# FM33L0XXD register map
File version: 1.0
CPU: SC000 r1p0, little endian, no MPU, FPU, 8 interrupt priority bits
Registers are 32-bit, read-write, reset 0x0 unless marked. A register's access mark holds for its fields unless they carry their own. Offsets are from the block's base; [hi:lo] are bit positions; {n}, {i} and the like mark numbered series.

## COMPCOM — COMPCOM module information
Base 0x40012848
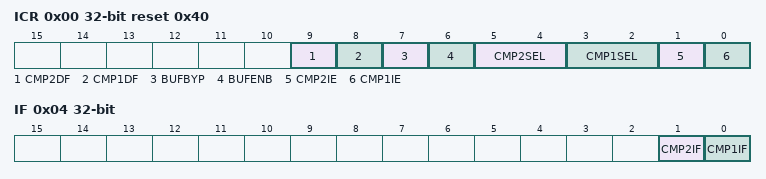
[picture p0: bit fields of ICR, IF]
0x00 ICR reset 0x40
  [9] CMP2DF — CMP2DF field description
  [8] CMP1DF — CMP1DF field description
  [7] BUFBYP — BUFBYP field description
  [6] BUFENB — BUFENB field description
  [5:4] CMP2SEL — CMP2SEL field description
  [3:2] CMP1SEL — CMP1SEL field description
  [1] CMP2IE — CMP2IE field description
  [0] CMP1IE — CMP1IE field description
0x04 IF
  [1] CMP2IF — CMP2IF field description
  [0] CMP1IF — CMP1IF field description

## CRC — CRC module information
Base 0x40010000
0x00 CRCDR reset 0xFFFFFFFF
  [31:0] CRCDR — CRCDR field description
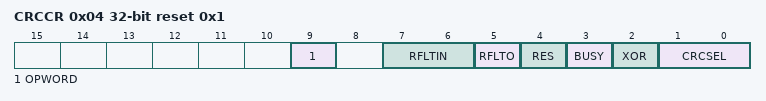
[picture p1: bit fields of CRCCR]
0x04 CRCCR reset 0x1
  [9] OPWORD — OP_WORD field description
  [7:6] RFLTIN — RFLTIN field description
  [5] RFLTO — RFLTO field description
  [4] RES ro — RES field description
  [3] BUSY ro — BUSY field description
  [2] XOR — XOR field description
  [1:0] CRCSEL — CRCSEL field description
0x08 CRCCAL reset 0xFFFFFFFF
  [31:0] LFSR — LFSR field description
0x0C CRCXOR
  [31:0] XOR — CRC_XOR field description
0x1C CRCPOLY reset 0x1021
  [31:0] POLY — CRC_POLY field description

## DBG — DBG module information
Base 0x40000000
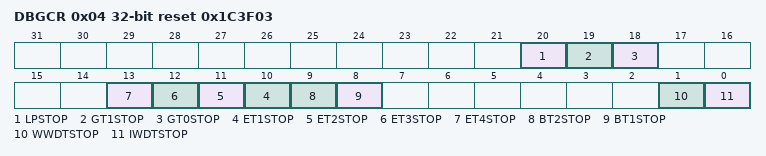
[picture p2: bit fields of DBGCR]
0x04 DBGCR reset 0x1C3F03
  [20] LPSTOP — LP_STOP field description
  [19] GT1STOP — GT1_STOP field description
  [18] GT0STOP — GT0_STOP field description
  [n+9] ET{n}STOP (n=1..4) — ET{n}_STOP field description
  [9] BT2STOP — BT2_STOP field description
  [8] BT1STOP — BT1_STOP field description
  [1] WWDTSTOP — WWDT_STOP field description
  [0] IWDTSTOP — IWDT_STOP field description

## DISP — DISP module information
Base 0x40010C00
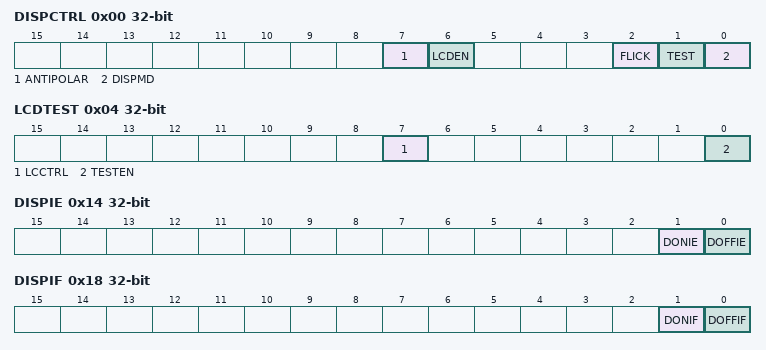
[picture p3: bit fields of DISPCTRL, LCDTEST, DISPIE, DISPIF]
0x00 DISPCTRL
  [7] ANTIPOLAR — ANTIPOLAR field description
  [6] LCDEN — LCDEN field description
  [2] FLICK — FLICK field description
  [1] TEST — TEST field description
  [0] DISPMD — DISPMD field description
0x04 LCDTEST
  [7] LCCTRL — LCCTRL field description
  [0] TESTEN — TESTEN field description
0x08 DF
  [7:0] DF — DF field description
0x0C TON
  [7:0] TON — TON field description
0x10 TOFF
  [7:0] TOFF — TOFF field description
0x14 DISPIE
  [1] DONIE — DONIE field description
  [0] DOFFIE — DOFFIE field description
0x18 DISPIF
  [1] DONIF — DONIF field description
  [0] DOFFIF — DOFFIF field description
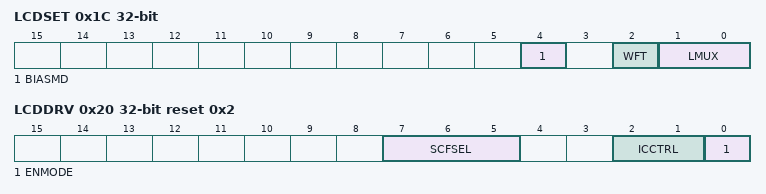
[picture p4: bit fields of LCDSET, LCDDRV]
0x1C LCDSET
  [4] BIASMD — BIASMD field description
  [2] WFT — WFT field description
  [1:0] LMUX — LMUX field description
0x20 LCDDRV reset 0x2
  [7:5] SCFSEL — SCFSEL field description
  [2:1] ICCTRL — IC_CTRL field description
  [0] ENMODE — ENMODE field description
{0x24+4i} DISPDATA{i} (i=0..9)
  [31:0] DSDA{i} — DSDA{i} field description
0x4C LCDBIAS
  [3:0] DSDA9 — DSDA9 field description
0x50 COMEN
  [3:0] COMEN — COMEN field description
0x54 SEGEN0
  [31:0] SEGEN0 — SEGEN0 field description
0x58 SEGEN1
  [11:0] SEGEN1 — SEGEN1 field description

## DMAC — DMAC module information
Base 0x40000400
0x00 GLOBALCTRL
  [0] DMACENABLE — DMACENABLE field description
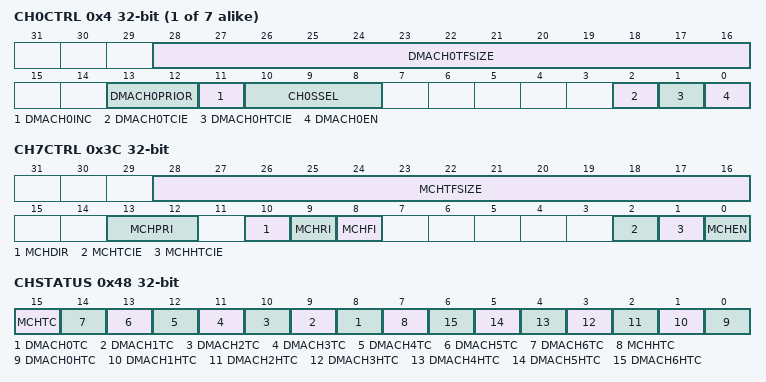
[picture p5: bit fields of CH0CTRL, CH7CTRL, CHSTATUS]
{0x4+8i} CH{i}CTRL (i=0..6)
  [28:16] DMACH{i}TFSIZE — DMACH{i}_TFSIZE field description
  [13:12] DMACH{i}PRIOR — DMACH{i}_PRIOR field description
  [11] DMACH{i}INC — DMACH{i}_INC field description
  [10:8] CH{i}SSEL — CH{i}_SSEL field description
  [2] DMACH{i}TCIE — DMACH{i}_TC_IE field description
  [1] DMACH{i}HTCIE — DMACH{i}_HTC_IE field description
  [0] DMACH{i}EN — DMACH{i}_EN field description
{0x8+8i} CH{i}RAMADDR (i=0..6)
  [14:0] DMACH{i}ADDR — DMACH{i}_ADDR field description
0x3C CH7CTRL
  [28:16] MCHTFSIZE — MCHTFSIZE field description
  [13:12] MCHPRI — MCHPRI field description
  [10] MCHDIR — MCHDIR field description
  [9] MCHRI — MCHRI field description
  [8] MCHFI — MCHFI field description
  [2] MCHTCIE — MCHTC_IE field description
  [1] MCHHTCIE — MCHHTC_IE field description
  [0] MCHEN — MCHEN field description
0x40 CH7FLSADDR
  [15:0] MCHFLASD — MCHFLASD field description
0x44 CH7RAMADDR
  [12:0] MCHRAMAD — MCHRAMAD field description
0x48 CHSTATUS
  [15] MCHTC — MCHTC field description
  [n+8] DMACH{n}TC (n=0..6) — DMACH{n}_TC field description
  [7] MCHHTC — MCHHTC field description
  [n] DMACH{n}HTC (n=0..6) — DMACH{n}_HTC field description
